# ATA5505 device description
Architecture: AVR8; Family: megaAVR
Registers are 8-bit, access not given, no defined reset value unless marked. A register's access mark holds for its fields unless they carry their own. Offsets are from the block's base; [hi:lo] are bit positions.

## FUSE
Instances: FUSE 0 in fuses
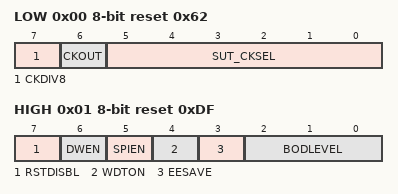
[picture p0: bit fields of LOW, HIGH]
0x00 LOW reset 0x62
  [7] CKDIV8 — Divide clock by 8 internally
  [6] CKOUT — Clock output on PORTB5
  [5:0] SUT_CKSEL — Select Clock source
    0=Ext. Clock; Start-up time PWRDWN/RESET: 6 CK/14 CK + 0 ms; 16=Ext. Clock; Start-up time PWRDWN/RESET: 6 CK/14 CK + 4 ms; 32=Ext. Clock; Start-up time PWRDWN/RESET: 6 CK/14 CK + 64 ms; 2=Int. RC Osc. 8 MHz; Start-up time PWRDWN/RESET: 6 CK/14 CK + 0 ms; 18=Int. RC Osc. 8 MHz; Start-up time PWRDWN/RESET: 6 CK/14 CK + 4 ms; 34=Int. RC Osc. 8 MHz; Start-up time PWRDWN/RESET: 6 CK/14 CK + 64 ms; 3=WD. Osc. 128 kHz; Start-up time PWRDWN/RESET: 6 CK/14 CK + 0 ms; 19=WD. Osc. 128 kHz; Start-up time PWRDWN/RESET: 6 CK/14 CK + 4 ms; 35=WD. Osc. 128 kHz; Start-up time PWRDWN/RESET: 6 CK/14 CK + 64 ms; 4=Ext. Low-Freq. Crystal; Start-up time PWRDWN/RESET: 1024 CK 4 ms; 20=Ext. Low-Freq. Crystal; Start-up time PWRDWN/RESET: 1024 CK + 64 ms; 36=Ext. Low-Freq. Crystal; Start-up time PWRDWN/RESET: 32768 CK + 64 ms; 8=Ext. Ceramic Res. 0.4-0.9 MHz; Start-up time PWRDWN/RESET: 258 CK/14 CK + 4.1 ms; 24=Ext. Ceramic Res. 0.4-0.9 MHz; Start-up time PWRDWN/RESET: 258 CK/14 CK + 65 ms; 40=Ext. Ceramic Res. 0.4-0.9 MHz; Start-up time PWRDWN/RESET: 1024 CK /14 CK + 0 ms; 56=Ext. Ceramic Res. 0.4-0.9 MHz; Start-up time PWRDWN/RESET: 1024 CK /14 CK + 4.1 ms; 9=Ext. Ceramic Res. 0.4-0.9 MHz; Start-up time PWRDWN/RESET: 1024 CK /14 CK + 65 ms; 25=Ext. Crystal Osc. 0.4-0.9 MHz; Start-up time PWRDWN/RESET: 16384 CK/14 CK + 0 ms; 41=Ext. Crystal Osc. 0.4-0.9 MHz; Start-up time PWRDWN/RESET: 16384 CK/14 CK + 4.1 ms; 57=Ext. Crystal Osc. 0.4-0.9 MHz; Start-up time PWRDWN/RESET: 16384 CK/14 CK + 65 ms; 10=Ext. Ceramic Res. 0.9-3.0 MHz; Start-up time PWRDWN/RESET: 258 CK/14 CK + 4.1 ms; 26=Ext. Ceramic Res. 0.9-3.0 MHz; Start-up time PWRDWN/RESET: 258 CK/14 CK + 65 ms; 42=Ext. Ceramic Res. 0.9-3.0 MHz; Start-up time PWRDWN/RESET: 1024 CK /14 CK + 0 ms; 58=Ext. Ceramic Res. 0.9-3.0 MHz; Start-up time PWRDWN/RESET: 1024 CK /14 CK + 4.1 ms; 11=Ext. Ceramic Res. 0.9-3.0 MHz; Start-up time PWRDWN/RESET: 1024 CK /14 CK + 65 ms; 27=Ext. Crystal Osc. 0.9-3.0 MHz; Start-up time PWRDWN/RESET: 16384 CK/14 CK + 0 ms; 43=Ext. Crystal Osc. 0.9-3.0 MHz; Start-up time PWRDWN/RESET: 16384 CK/14 CK + 4.1 ms; 59=Ext. Crystal Osc. 0.9-3.0 MHz; Start-up time PWRDWN/RESET: 16384 CK/14 CK + 65 ms; 12=Ext. Ceramic Res. 3.0-8.0 MHz; Start-up time PWRDWN/RESET: 258 CK/14 CK + 4.1 ms; 28=Ext. Ceramic Res. 3.0-8.0 MHz; Start-up time PWRDWN/RESET: 258 CK/14 CK + 65 ms; 44=Ext. Ceramic Res. 3.0-8.0 MHz; Start-up time PWRDWN/RESET: 1024 CK /14 CK + 0 ms; 60=Ext. Ceramic Res. 3.0-8.0 MHz; Start-up time PWRDWN/RESET: 1024 CK /14 CK + 4.1 ms; 13=Ext. Ceramic Res. 3.0-8.0 MHz; Start-up time PWRDWN/RESET: 1024 CK /14 CK + 65 ms; 29=Ext. Crystal Osc. 3.0-8.0 MHz; Start-up time PWRDWN/RESET: 16384 CK/14 CK + 0 ms; 45=Ext. Crystal Osc. 3.0-8.0 MHz; Start-up time PWRDWN/RESET: 16384 CK/14 CK + 4.1 ms; 61=Ext. Crystal Osc. 3.0-8.0 MHz; Start-up time PWRDWN/RESET: 16384 CK/14 CK + 65 ms; 14=Ext. Ceramic Res. 8.0-16.0 MHz; Start-up time PWRDWN/RESET: 258 CK/14 CK + 4.1 ms; 30=Ext. Ceramic Res. 8.0-16.0 MHz; Start-up time PWRDWN/RESET: 258 CK/14 CK + 65 ms; 46=Ext. Ceramic Res. 8.0-16.0 MHz; Start-up time PWRDWN/RESET: 1024 CK /14 CK + 0 ms; 62=Ext. Ceramic Res. 8.0-16.0 MHz; Start-up time PWRDWN/RESET: 1024 CK /14 CK + 4.1 ms; 15=Ext. Ceramic Res. 8.0-16.0 MHz; Start-up time PWRDWN/RESET: 1024 CK /14 CK + 65 ms; 31=Ext. Crystal Osc. 8.0-16.0 MHz; Start-up time PWRDWN/RESET: 16384 CK/14 CK + 0 ms; 47=Ext. Crystal Osc. 8.0-16.0 MHz; Start-up time PWRDWN/RESET: 16384 CK/14 CK + 4.1 ms; 63=Ext. Crystal Osc. 8.0-16.0 MHz; Start-up time PWRDWN/RESET: 16384 CK/14 CK + 65 ms
0x01 HIGH reset 0xDF
  [7] RSTDISBL — Reset Disabled (Enable PB7 as i/o pin)
  [6] DWEN — Debug Wire enable
  [5] SPIEN — Serial program downloading (SPI) enabled
  [4] WDTON — Watch-dog Timer always ON
  [3] EESAVE — Preserve EEPROM through the Chip Erase cycle
  [2:0] BODLEVEL — Brown-out Detector trigger level
    4=Brown-out detection at VCC=4.3 V; 5=Brown-out detection at VCC=2.7 V; 6=Brown-out detection at VCC=1.8 V; 3=Brown-out detection at VCC=2.3 V; 2=Brown-out detection at VCC=2.2 V; 1=Brown-out detection at VCC=1.9 V; 0=Brown-out detection at VCC=2.0 V; 7=Brown-out detection disabled
0x02 EXTENDED reset 0xFF
  [0] SELFPRGEN — Self Programming enable
